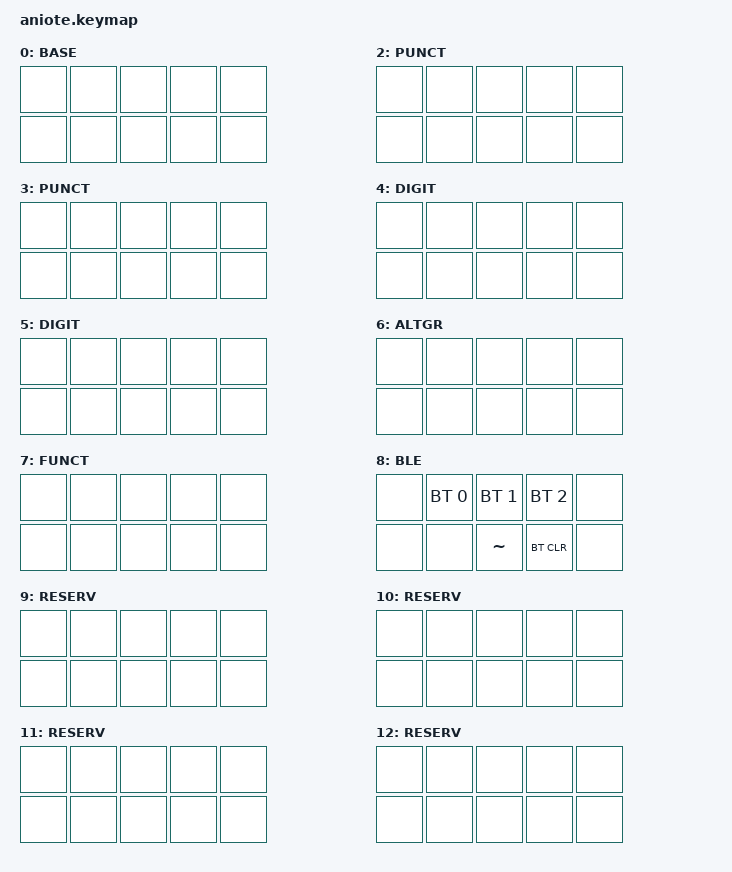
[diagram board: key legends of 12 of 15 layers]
#include <behaviors.dtsi>
#include <dt-bindings/zmk/keys.h>
#include <dt-bindings/zmk/bt.h>
#include <dt-bindings/zmk/outputs.h>
#include <dt-bindings/zmk/mouse.h>

// Timeouts
#define TIMEOUT_LT 200
#define TIMEOUT_TD 200
#define TIMEOUT_SL 3000
#define TIMEOUT_SK 5000
#define TIMEOUT_COMBO 80

/***************** Keyboard  ******************
*   U1L  U2L  U3L  U4L  U5L       U5R  U4R  U3R  U2R  U1R 
*    T_L  I_L  D3L  R_L  P_L       P_R  R_R  M_R  I_R  T_R 
**********************************************/

#define U1R  0
#define U2R  1
#define U3R  2
#define U4R  3
#define U5R  4
#define T_R  5
#define I_R  6
#define M_R  7
#define R_R  8
#define P_R  9

#define X____ 5
#define _x___ 6
#define __x__ 7
#define ___x_ 8
#define ____x 9
#define Xx___ 5 6
#define X_x__ 5 7
#define X__x_ 5 8
#define X___x 5 9
#define _xx__ 6 7
#define _x_x_ 6 8
#define _x__x 6 9
#define __xx_ 7 8
#define __x_x 7 9
#define ___xx 8 9
#define Xxx__ 5 6 7
#define Xx_x_ 5 6 8
#define Xx__x 5 6 9
#define X_xx_ 5 7 8
#define X_x_x 5 7 9
#define X__xx 5 8 9
#define _xxx_ 6 7 8
#define _xx_x 6 7 9
#define _x_xx 6 8 9
#define __xxx 7 8 9
#define Xxxx_ 5 6 7 8
#define Xxx_x 5 6 7 9
#define Xx_xx 5 6 8 9
#define X_xxx 5 7 8 9
#define _xxxx 6 7 8 9
#define Xxxxx 5 6 7 8 9

#define U1L  4
#define U2L  3
#define U3L  2
#define U4L  1
#define U5L  0
#define T_L  9
#define I_L  8
#define M_L  7
#define R_L  6
#define P_L  5

#define A_RU F
#define B_RU COMMA
#define C_RU W
#define D_RU L
#define E_RU T
#define F_RU A
#define G_RU U
#define H_RU LBKT
#define I_RU B
#define J_RU Q
#define K_RU R
#define L_RU K
#define M_RU V
#define N_RU Y
#define O_RU J
#define P_RU G
#define Q_RU DOT
#define R_RU H
#define S_RU C
#define T_RU N
#define U_RU E
#define V_RU D
#define W_RU SEMI
#define X_RU Z
#define Y_RU S
#define Z_RU P

#define SOFT    M
#define SOFT_RU M
#define CH      X
#define CH_RU   X
#define SH      I
#define SH_RU   I
#define SCH     O
#define SCH_RU  O
#define AE      SQT
#define AE_RU   SQT
#define HARD    RBKT
#define HARD_RU RBKT
#define YO      GRAVE
#define YO_RU   GRAVE

#define COMMA_RU LS(FSLH)
#define DOT_RU   FSLH
#define SEMI_RU  LS(N4)
#define COLON_RU LS(N6)
#define FSLH_RU  KP_DIVIDE
#define QMARK_RU LS(N7)
#define SQT_RU   LA(O)
#define DQT_RU   LS(N2)
#define SPC_RU SPC

#define GRAVE_RU GRAVE
#define N6_RU N6
#define LBRC_RU LBRC
#define LEFT_RU LEFT
#define RBKT_RU RBKT
#define LBKT_RU LBKT
#define N2_RU N2
#define N4_RU N4
#define EQUAL_RU EQUAL 
#define N9_RU N9
#define HASH_RU HASH
#define HOME_RU HOME
#define EXCL_RU EXCL
#define N3_RU N3
#define AT_RU AT
#define UNDER_RU UNDER 
#define N7_RU N7
#define GT_RU GT
#define MINUS_RU MINUS
#define RPAR_RU RPAR
#define RIGHT_RU RIGHT
#define PIPE_RU PIPE
#define N8_RU N8
#define RBRC_RU RBRC
#define PLUS_RU PLUS
#define PGUP_RU PGUP
#define DOLLAR_RU DOLLAR
#define N5_RU N5
#define STAR_RU STAR
#define N1_RU N1
#define PERCENT_RU PERCENT 
#define TILDE_RU TILDE
#define AMPS_RU AMPS
#define N0_RU N0
#define LPAR_RU LPAR
#define DOWN_RU DOWN
#define LT_RU LT
#define INSERT_RU INSERT
#define BSLH_RU BSLH
#define PGDN_RU PGDN
#define CARET_RU CARET 
#define UP_RU UP
#define END_RU END
#define LCTRL_RU LCTRL
#define LSHFT_RU LSHFT

#define THUMB  &kp SPACE
#define _  &none
#define _____  &none
#define ______RU  &none
#define REPEAT &key_repeat
#define RESET  &rst
#define BT_USB &bt_usb BLE OUT_TOG

// Layers

#define BASE 0
#define BASE_RU 1
#define PUNCT 2
#define PUNCT_RU 3
#define DIGIT 4
#define DIGIT_RU 5
#define ALTGR 6
#define FUNCT 7

#define BLE 8

#define SL1 9
#define SL1_RU 10
#define SL2 11
#define SL3 12
#define SL4 13
#define SL5 14

#define PENTI 0 1 2 3 4 5 6 7 9 10 11 12 13

#define CMB(CHORD, BASE_BIND, PUNCT_BIND, DIGIT_BIND, ALTGR_BIND, FUNCT_BIND, SL1_BIND, SL2_BIND, SL3_BIND, SL4_BIND, SL5_BIND) \
combo_base_##CHORD      { timeout-ms = <TIMEOUT_COMBO>; bindings = <BASE_BIND>      ; key-positions = <CHORD>; layers = <BASE>;  }; \
combo_base_##CHORD##RU  { timeout-ms = <TIMEOUT_COMBO>; bindings = <BASE_BIND##_RU> ; key-positions = <CHORD>; layers = <BASE_RU>;  }; \
combo_punct_##CHORD     { timeout-ms = <TIMEOUT_COMBO>; bindings = <PUNCT_BIND>     ; key-positions = <CHORD>; layers = <PUNCT>; }; \
combo_punct_##CHORD##RU { timeout-ms = <TIMEOUT_COMBO>; bindings = <PUNCT_BIND##_RU>; key-positions = <CHORD>; layers = <PUNCT_RU>; }; \
combo_digit_##CHORD     { timeout-ms = <TIMEOUT_COMBO>; bindings = <DIGIT_BIND>     ; key-positions = <CHORD>; layers = <DIGIT>; }; \
combo_digit_##CHORD##RU { timeout-ms = <TIMEOUT_COMBO>; bindings = <DIGIT_BIND##_RU>; key-positions = <CHORD>; layers = <DIGIT_RU>; }; \
combo_altgr_##CHORD     { timeout-ms = <TIMEOUT_COMBO>; bindings = <ALTGR_BIND>     ; key-positions = <CHORD>; layers = <ALTGR>; }; \
combo_funct_##CHORD     { timeout-ms = <TIMEOUT_COMBO>; bindings = <FUNCT_BIND>     ; key-positions = <CHORD>; layers = <FUNCT>; }; \
combo_sl1_##CHORD       { timeout-ms = <TIMEOUT_COMBO>; bindings = <SL1_BIND>       ; key-positions = <CHORD>; layers = <SL1>; }; \
combo_sl1_##CHORD##RU   { timeout-ms = <TIMEOUT_COMBO>; bindings = <SL1_BIND##_RU>  ; key-positions = <CHORD>; layers = <SL1_RU>; }; \
combo_sl2_##CHORD { timeout-ms = <TIMEOUT_COMBO>; bindings = <SL2_BIND>; key-positions = <CHORD>; layers = <SL2>; }; \
combo_sl3_##CHORD { timeout-ms = <TIMEOUT_COMBO>; bindings = <SL3_BIND>; key-positions = <CHORD>; layers = <SL3>; }; \
combo_sl4_##CHORD { timeout-ms = <TIMEOUT_COMBO>; bindings = <SL4_BIND>; key-positions = <CHORD>; layers = <SL4>; }; \
combo_sl5_##CHORD { timeout-ms = <TIMEOUT_COMBO>; bindings = <SL5_BIND>; key-positions = <CHORD>; layers = <SL5>; };

// tune-up default behaviors
&sk { release-after-ms = <TIMEOUT_SK>; quick-release; };
&sl { release-after-ms = <TIMEOUT_SL>; };
&lt { tapping-term-ms  = <TIMEOUT_LT>; flavor = "balanced"; retro-tap;} ;


/ {
    combos {
        compatible = "zmk,combos";

        combo_boot   { bindings = <&bootloader>    ; key-positions = < 0 2 4 5 7 9 >; timeout-ms = <TIMEOUT_COMBO>; };
        combo_studio { bindings = <&studio_unlock> ; key-positions = < 1 2 3 6 7 8 >; timeout-ms = <TIMEOUT_COMBO>; };
        combo_ble    { bindings = <BT_USB>         ; key-positions = < 4 >          ; timeout-ms = <TIMEOUT_COMBO>; };
        combo_caps   { bindings = <&kp CAPSLOCK>   ; key-positions = < 0 1 2 3 4 >  ; timeout-ms = <TIMEOUT_COMBO>; };

        combo_eng_r  { bindings = <&to_eng_r>      ; key-positions = < 5 2 3 4 >    ; timeout-ms = <TIMEOUT_COMBO>; };
        combo_rus_r  { bindings = <&to_rus_r>      ; key-positions = < 0 7 8 9 >    ; timeout-ms = <TIMEOUT_COMBO>; };
        combo_eng_l  { bindings = <&to_eng_l>      ; key-positions = < 9 0 1 2 >    ; timeout-ms = <TIMEOUT_COMBO>; };
        combo_rus_l  { bindings = <&to_rus_r>      ; key-positions = < 4 5 6 7 >    ; timeout-ms = <TIMEOUT_COMBO>; };

        combo_repeat  { bindings = <&key_repeat>   ; key-positions = < 2 >          ; timeout-ms = <TIMEOUT_COMBO>; layers = < PENTI > ; };
        combo_reset   { bindings = <&rst>          ; key-positions = < 0 >          ; timeout-ms = <TIMEOUT_COMBO>; layers = < PENTI > ; };

        //    CHORD   BASE           PUNCT          DIGIT           ALTGR           FUNCT         SL1          SL2          SL3          SL4          SL5
        // ---------------------------------------------------------------------------------------------------------------------------------------------
        CMB ( X____ , &lt SL1 SPC  , &lt SL1 SPC  , &lt SL1 SPC   , &lt SL1 SPC   , &lt SL1 SPC , _____      , &kt LSHFT  , &to_punct  , &to_digit  , &kt LCTRL )
        CMB ( ____x , &lt SL1_RU N , &lt SL5 RPAR , &lt SL5 RIGHT , &mo SL5       , &mo SL5     , &sk LCTRL  , &sk ALTGR  , _____      , _____      , _____     )
        CMB ( _x___ , &lt SL2 S    , &lt SL2 STAR , &lt SL2 N1    , &mo SL2       , &lt SL2 F1  , &sk LSHFT  , _____      , &kp TAB    , &kp ESC    , _____     )
        CMB ( __x__ , &lt SL3 E    , &lt SL3 LBKT , &lt SL3 N2    , &lt SL3 YO    , &lt SL3 F2  , &sl PUNCT  , &kp BSPC   , _____      , &sl FUNCT  , _____     )
        CMB ( ___x_ , &lt SL4 I    , &lt SL4 EXCL , &lt SL4 N3    , &mo SL4       , &lt SL4 F3  , &sl DIGIT  , &kp ENTER  , &sl FUNCT  , _____      , _____     )
        CMB ( X__x_ , &kp A        , &kp GRAVE    , &kp N6        , _____         , &kp F6      , _____      , _____      , _____      , _____      , _____     )
        CMB ( X_xx_ , &kp B        , &kp LBRC     , &kp LEFT      , _____         , _____       , _____      , _____      , _____      , _____      , _____     )
        CMB ( _x_x_ , &kp C        , &kp RBKT     , &kp COMMA     , _____         , &kp LG(C)   , _____      , _____      , _____      , _____      , _____     )
        CMB ( X___x , &kp D        , &kp FSLH     , &kp DOT       , _____         , _____       , _____      , _____      , _____      , _____      , _____     )
        CMB ( Xx___ , &kp F        , &kp QMARK    , &kp N4        , _____         , &kp F4      , _____      , _____      , _____      , _____      , _____     )
        CMB ( ___xx , &kp G        , &kp EQUAL    , &kp N9        , _____         , &kp F9      , _____      , _____      , _____      , _____      , _____     )
        CMB ( Xx__x , &kp H        , &kp HASH     , &kp HOME      , _____         , _____       , _____      , _____      , _____      , _____      , _____     )
        CMB ( _x__x , &kp J        , &kp SEMI     , &kp COLON     , _____         , _____       , _____      , _____      , _____      , _____      , _____     )
        CMB ( _xxxx , &kp K        , &kp AT       , _____         , _____         , RESET       , _____      , _____      , _____      , _____      , _____     )
        CMB ( _xx__ , &kp L        , &kp UNDER    , &kp N7        , _____         , &kp F7      , _____      , _____      , _____      , _____      , _____     )
        CMB ( __xxx , &kp M        , &kp GT       , &kp MINUS     , &kp LA(MINUS) , &kp F12     , _____      , _____      , _____      , _____      , _____     )
        CMB ( __xx_ , &kp O        , &kp PIPE     , &kp N8        , _____         , &kp F8      , _____      , _____      , _____      , _____      , _____     )
        CMB ( Xxxx_ , &kp P        , &kp RBRC     , &kp PLUS      , _____         , &kp LG(V)   , _____      , _____      , _____      , _____      , _____     )
        CMB ( Xx_x_ , &kp Q        , &kp SQT      , &kp PGUP      , _____         , _____       , _____      , _____      , _____      , _____      , _____     )
        CMB ( X_x__ , &kp R        , &kp DOLLAR   , &kp N5        , _____         , &kp F5      , _____      , _____      , _____      , _____      , _____     )
        CMB ( X_xxx , &kp T        , &kp PERCENT  , &kp TILDE     , _____         , _____       , _____      , _____      , _____      , _____      , _____     )
        CMB ( _xxx_ , &kp U        , &kp AMPS     , &kp N0        , _____         , &kp F10     , _____      , _____      , _____      , _____      , _____     )
        CMB ( _x_xx , &kp V        , &kp LPAR     , &kp DOWN      , _____         , _____       , _____      , _____      , _____      , _____      , _____     )
        CMB ( Xxxxx , &kp W        , &kp LT       , &kp INSERT    , _____         , &kp LG(V)   , _____      , _____      , _____      , _____      , _____     )
        CMB ( Xx_xx , &kp X        , &kp BSLH     , &kp PGDN      , _____         , _____       , _____      , _____      , _____      , _____      , _____     )
        CMB ( X__xx , &kp Y        , &kp CARET    , &kp UP        , _____         , _____       , _____      , _____      , _____      , _____      , _____     )
        CMB ( Xxx__ , &kp Z        , &kp DQT      , &kp END       , _____         , &kp F11     , _____      , _____      , _____      , _____      , _____     )
        CMB ( __x_x , &kp SOFT     , &kp HARD     , _____         , _____         , _____       , _____      , _____      , _____      , _____      , _____     )
        CMB ( _xx_x , &kp CH       , _____        , _____         , _____         , _____       , _____      , _____      , _____      , _____      , _____     )
        CMB ( X_x_x , &kp SH       , &kp SCH      , _____         , _____         , _____       , _____      , _____      , _____      , _____      , _____     )
        CMB ( Xxx_x , &kp AE       , _____        , _____         , _____         , _____       , _____      , _____      , _____      , _____      , _____     )
    };

    macros {
        to_eng_l: to_eng_l {
            compatible = "zmk,behavior-macro";
            #binding-cells = <0>;
            bindings = <&to BASE &kp F18 &kp CAPSLOCK>;};
        to_rus_l: to_rus_l {
            compatible = "zmk,behavior-macro";
            #binding-cells = <0>;
            bindings = <&to BASE_RU &kp F19 &kp CAPSLOCK>;};
        to_eng_r: to_eng_r {
            compatible = "zmk,behavior-macro";
            #binding-cells = <0>;
            bindings = <&to BASE &kp F18 &kp CAPSLOCK>;};
        to_rus_r: to_rus_r {
            compatible = "zmk,behavior-macro";
            #binding-cells = <0>;
            bindings = <&to BASE_RU &kp F19>;};
        rst: rst {
            compatible = "zmk,behavior-macro";
            #binding-cells = <0>;
            bindings = <&to 0 &kt_off LSHFT &kt_off LCTRL &kt_off LALT &kt_off LGUI>;};
        to_punct: to_punct {
            compatible = "zmk,behavior-macro";
            #binding-cells = <0>;
            bindings = <&tog PUNCT &tog_off DIGIT>;};
        to_digit: to_funct {
            compatible = "zmk,behavior-macro";
            #binding-cells = <0>;
            bindings = <&tog DIGIT &tog_off PUNCT>;};
    };

    behaviors {
        td_copy_cut: tap_dance_copy_cut {
            compatible = "zmk,behavior-tap-dance";
            #binding-cells = <0>;
            tapping-term-ms = < TIMEOUT_TD >;
            bindings = <&kp LG(C)>, <&kp LG(X)>;};
        kt_off: key_toggle_off_only {
            compatible = "zmk,behavior-key-toggle";
            #binding-cells = <1>;
            display-name = "Key Toggle OFF";
            toggle-mode = "off";};
        tog_off: toggle_layer_off_only {
            compatible = "zmk,behavior-toggle-layer";
            #binding-cells = <1>;
            display-name = "Toggle Layer OFF";
            toggle-mode = "off";};
         bt_usb: behavior_mo_tog {
            compatible = "zmk,behavior-hold-tap";
            #binding-cells = <2>;
            flavor = "hold-preferred";
            tapping-term-ms = <200>;
            bindings = <&mo>, <&out>; };
    };
};

/ {
    keymap {
        compatible = "zmk,keymap";

        BASE {
            display-name = "BASE";
            bindings = <
                _____           _____               _____               _____               _____
                _____           _____               _____               _____               _____
            >;
        };

        BASE_RU { bindings = < _ _ _ _ _ _ _ _  >; };

        PUNCT {
            display-name = "PUNCT";
            bindings = <
                _____           _____               _____               _____               _____
                _____           _____               _____               _____               _____
          >;
        };

        PUNCT_RU {
            display-name = "PUNCT";
            bindings = <
                _____           _____               _____               _____               _____
                _____           _____               _____               _____               _____
          >;
        };

        DIGIT {
            display-name = "DIGIT";
            bindings = <
                _____           _____               _____               _____               _____
                _____           _____               _____               _____               _____
            >;
        };

        DIGIT_RU {
            display-name = "DIGIT";
            bindings = <
                _____           _____               _____               _____               _____
                _____           _____               _____               _____               _____
            >;
        };

        
        ALTGR {
            display-name = "ALTGR";
            bindings = <
                _____           _____               _____               _____               _____
                _____           _____               _____               _____               _____
            >;
        };

        FUNCT {
            display-name = "FUNCT";
            bindings = <
                _____           _____               _____               _____               _____
                _____           _____               _____               _____               _____
            >;
        };
                
        BLE {
            display-name = "BLE";
            bindings = <
                _____           &bt BT_SEL 0        &bt BT_SEL 1        &bt BT_SEL 2        _____
                _____           _____               &kp TILDE           &bt BT_CLR          _____
            >;
        };

        SL1 {
            display-name = "RESERV";
            bindings = <
                _____           _____               _____               _____               _____
                _____           _____               _____               _____               _____
            >;
        };

        SL1_RU {
            display-name = "RESERV";
            bindings = <
                _____           _____               _____               _____               _____
                _____           _____               _____               _____               _____
            >;
        };

        SL2 {
            display-name = "RESERV";
            bindings = <
                _____           _____               _____               _____               _____
                _____           _____               _____               _____               _____
            >;
        };

        SL3 {
            display-name = "RESERV";
            bindings = <
                _____           _____               _____               _____               _____
                _____           _____               _____               _____               _____
            >;
        };

        SL4 {
            display-name = "RESERV";
            bindings = <
                _____           _____               _____               _____               _____
                _____           _____               _____               _____               _____
            >;
        };

        SL5 {
            display-name = "RESERV";
            bindings = <
                _____           _____               _____               _____               _____
                _____           _____               _____               _____               _____
            >;
        };

    };
};
    
